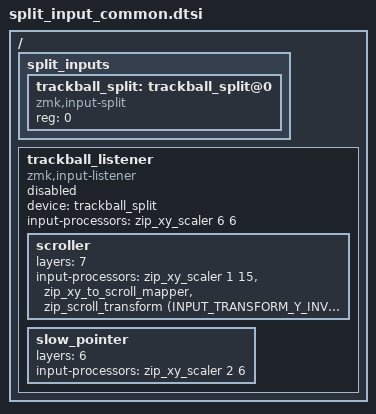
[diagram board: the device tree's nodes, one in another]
#include <dt-bindings/zmk/input_transform.h>
#include <input/processors.dtsi>

/ {
	split_inputs {
		#address-cells = <1>;
		#size-cells = <0>;

		trackball_split: trackball_split@0 {
			compatible = "zmk,input-split";
			reg = <0>;
		};
	};

	trackball_listener: trackball_listener {
		compatible = "zmk,input-listener";
		status = "disabled"; // overridden on central
		device = <&trackball_split>;

		input-processors = <&zip_xy_scaler 6 6>;

		/* layer-8 scroll override */
		scroller: scroller {
			layers = <7>;
			input-processors = <
									   &zip_xy_scaler 1 15                              // Scales the scroll speed
									   &zip_xy_to_scroll_mapper                         // Converts XY movement to scroll events
									   &zip_scroll_transform (INPUT_TRANSFORM_Y_INVERT) // Inverts the scroll direction
							   >;
		};

		/* layer-7 slow-pointer override */
		slow_pointer: slow_pointer {
			layers = <6>;
			input-processors = <&zip_xy_scaler 2 6>;
		};
	};
};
